# STM32F091xC register map
File version: 1.0
Registers are 32-bit, read-write, reset 0x0 unless marked. A register's access mark holds for its fields unless they carry their own. Offsets are from the block's base; [hi:lo] are bit positions.

## TIM14 — TIM
Base 0x40002000
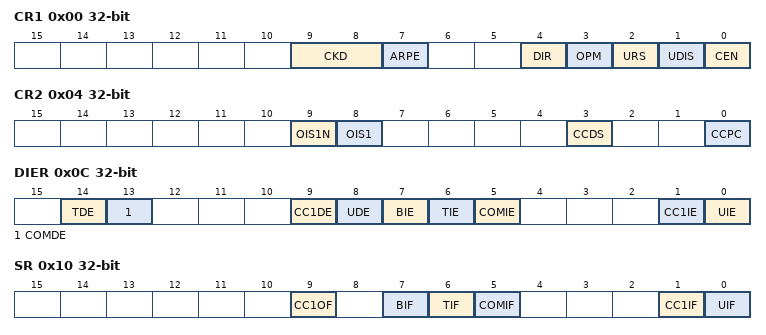
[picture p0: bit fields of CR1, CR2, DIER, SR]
0x00 CR1 — TIM control register 1
  [9:8] CKD — CKD[1:0] bits (clock division)
    0=DIV1 (tDTS=tCK_INT); 1=DIV2 (tDTS=2*tCK_INT); 2=DIV4 (tDTS=4*tCK_INT)
  [7] ARPE — Auto-reload preload enable
  [4] DIR — Direction
    0=UP (Timer counter counts up); 1=DOWN (Timer counter counts down)
  [3] OPM — One pulse mode
    1=SINGLE (Counter stops counting at the next update event); 0=REPETITIVE (Counter is not stopped at update event)
  [2] URS — Update request source
    0=REGULAR (Counter overflow/underflow, Setting the UG bit or Update generation through the slave mode controller generates an update request); 1=COUNTER (Only counter overflow/underflow generates an update request)
  [1] UDIS — Update disable
  [0] CEN — Counter enable
0x04 CR2 — TIM control register 2
  [9] OIS1N — Output Idle state 1 (OC1N output)
  [8] OIS1 — Output Idle state 1 (OC1 output)
  [3] CCDS — Capture/Compare DMA Selection
    0=CC (CCx DMA request sent when CCx event occurs); 1=UPDATE (CCx DMA requests sent when update event occurs)
  [0] CCPC — Capture/Compare Preloaded Control
0x08 SMCR — TIM slave Mode Control register
  [3] OCCS — OCREF clear selection
    0=OCREF_CLR (OCREF_CLR_INT is connected to the OCREF_CLR input); 1=ETR (OCREF_CLR_INT is connected to ETRF)
0x0C DIER — TIM DMA/interrupt enable register
  [14] TDE — Trigger DMA request enable
  [13] COMDE — COM DMA request enable
  [9] CC1DE — Capture/Compare 1 DMA request enable
  [8] UDE — Update DMA request enable
  [7] BIE — Break interrupt enable
  [6] TIE — Trigger interrupt enable
  [5] COMIE — COM interrupt enable
  [1] CC1IE — Capture/Compare 1 interrupt enable
  [0] UIE — Update interrupt enable
0x10 SR — TIM status register
  [9] CC1OF — Capture/Compare 1 Overcapture Flag
  [7] BIF — Break interrupt Flag
  [6] TIF — Trigger interrupt Flag
  [5] COMIF — COM interrupt Flag
  [1] CC1IF — Capture/Compare 1 interrupt Flag
  [0] UIF — Update interrupt Flag
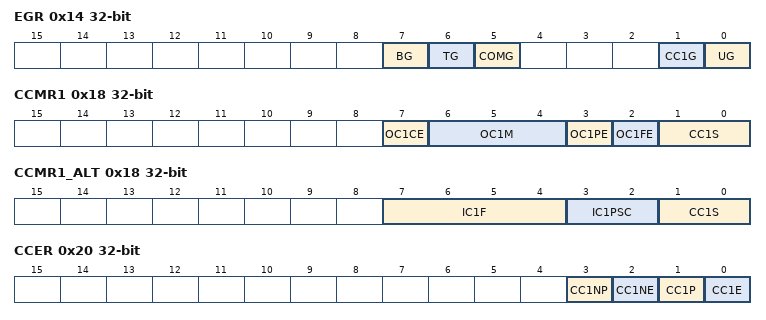
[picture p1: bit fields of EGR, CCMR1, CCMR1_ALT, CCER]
0x14 EGR — TIM event generation register
  [7] BG — Break Generation
  [6] TG — Trigger Generation
  [5] COMG — Capture/Compare Control Update Generation
  [1] CC1G — Capture/Compare 1 Generation
  [0] UG — Update Generation
0x18 CCMR1 — TIM capture/compare mode register 1
  [7] OC1CE — Output Compare 1Clear Enable
  [6:4] OC1M — OC1M[2:0] bits (Output Compare 1 Mode)
  [3] OC1PE — Output Compare 1 Preload enable
  [2] OC1FE — Output Compare 1 Fast enable
  [1:0] CC1S — CC1S[1:0] bits (Capture/Compare 1 Selection)
0x18 CCMR1_ALT (alternate view of CCMR1) — TIM capture/compare mode register 1
  [7:4] IC1F — IC1F[3:0] bits (Input Capture 1 Filter)
  [3:2] IC1PSC — IC1PSC[1:0] bits (Input Capture 1 Prescaler)
  [1:0] CC1S — CC1S[1:0] bits (Capture/Compare 1 Selection)
0x20 CCER — TIM capture/compare enable register
  [3] CC1NP — Capture/Compare 1 Complementary output Polarity
  [2] CC1NE — Capture/Compare 1 Complementary output enable
  [1] CC1P — Capture/Compare 1 output Polarity
  [0] CC1E — Capture/Compare 1 output enable
0x24 CNT — TIM counter register
  [15:0] CNT — Counter Value
0x28 PSC — TIM prescaler register
  [15:0] PSC — Prescaler Value
0x2C ARR — TIM auto-reload register
  [15:0] ARR — actual auto-reload Value
0x34 CCR1 — TIM capture/compare register 1
  [15:0] CCR1 — Capture/Compare 1 Value
0x4C DMAR — TIM DMA address for full transfer register
  [15:0] DMAB — DMA register for burst accesses
0x50 OR — TIM option register
  [1:0] TI1_RMP — TI1_RMP[1:0] bits (TIM14 Input 4 remap)

## TIM16 — TIM
Base 0x40014400
Same registers: TIM17 0x40014800
Registers as TIM14; these are added or differ:
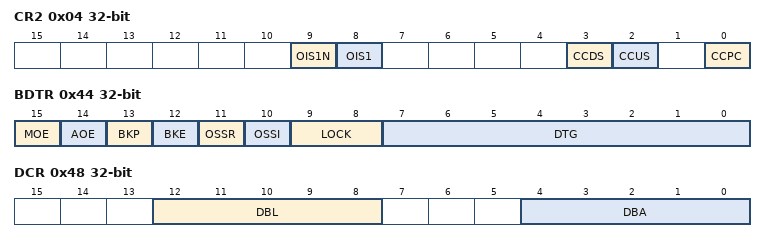
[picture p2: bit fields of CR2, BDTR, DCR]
0x04 CR2 — TIM control register 2
  [9] OIS1N — Output Idle state 1 (OC1N output)
  [8] OIS1 — Output Idle state 1 (OC1 output)
  [3] CCDS — Capture/Compare DMA Selection
    0=CC (CCx DMA request sent when CCx event occurs); 1=UPDATE (CCx DMA requests sent when update event occurs)
  [2] CCUS — Capture/Compare Control Update Selection
    0=ONLY (Capture/compare control bits are updated by setting the COMG bit only); 1=AND_TRGI (Capture/compare control bits are updated by setting the COMG bit or when a rising edge occurs on trigger input (TRGI))
  [0] CCPC — Capture/Compare Preloaded Control
0x30 RCR — TIM repetition counter register
  [7:0] REP — Repetition Counter Value
0x44 BDTR — TIM break and dead-time register
  [15] MOE — Main Output enable
  [14] AOE — Automatic Output enable
  [13] BKP — Break Polarity
    0=LOW (Break input BRK is active low); 1=HIGH (Break input BRK is active high)
  [12] BKE — Break enable
  [11] OSSR — Off-State Selection for Run mode
  [10] OSSI — Off-State Selection for Idle mode
  [9:8] LOCK — LOCK[1:0] bits (Lock Configuration)
    0=OFF (LOCK OFF - No bit is write protected); 1=LOCKLEVEL_1; 2=LOCKLEVEL_2; 3=LOCKLEVEL_3
  [7:0] DTG — DTG[0:7] bits (Dead-Time Generator set-up)
0x48 DCR — TIM DMA control register
  [12:8] DBL — DBL[4:0] bits (DMA Burst Length)
  [4:0] DBA — DBA[4:0] bits (DMA Base Address)
0x50 OR — TIM option register
